# ATA5835 device description
Architecture: AVR8; Family: megaAVR
Registers are 8-bit, access not given, no defined reset value unless marked. A register's access mark holds for its fields unless they carry their own. Offsets are from the block's base; [hi:lo] are bit positions.

## RXDSP
Instances: RXDSP 0x00
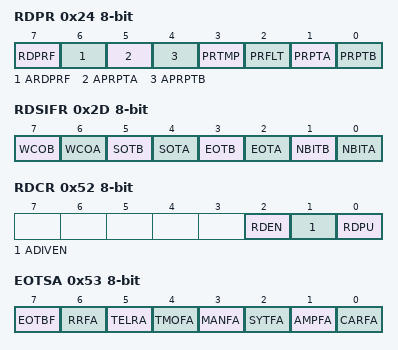
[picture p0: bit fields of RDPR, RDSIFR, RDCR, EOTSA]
0x24 RDPR — Rx DSP Power Reduction
  [7] RDPRF — Rx DSP Power Reduction Register Busy Flag
  [6] ARDPRF — Automatic Rx DSP Power Reduction Flag
  [5] APRPTA — Automatic Power Reduction Path A
  [4] APRPTB — Automatic Power Reduction Path B
  [3] PRTMP — Power Reduction Temperature Measurement
  [2] PRFLT — Power Reduction Digital Channel Filter
  [1] PRPTA — Power Reduction Demodulator and Receiving Path A
  [0] PRPTB — Power Reduction Demodulator and Receiving Path B
0x2D RDSIFR — Rx DSP Status Interrupt Flag Register
  [7] WCOB — Wake Check Ok Path B
  [6] WCOA — Wake Check Ok Path A
  [5] SOTB — Start Of Telegram Path B
  [4] SOTA — Start Of Telegram Path A
  [3] EOTB — End Of Telegram Path B
  [2] EOTA — End Of Telegram Path A
  [1] NBITB — New Bit Path B
  [0] NBITA — New Bit Path A
0x52 RDCR — Rx DSP Control Register
  [2] RDEN — Rx DSP Enable
  [1] ADIVEN — Divided ADC Clock Enable
  [0] RDPU — Rx DSP Power Up
0x53 EOTSA — End Of Telegram Status Path A
  [7] EOTBF — End Of Telegram Path B Fail
  [6] RRFA — RSSI Range Fail Path A
  [5] TELRA — Telegram Length Reached Path A
  [4] TMOFA — Time-Out Fail Path A
  [3] MANFA — Manchester Coding Fail Path A
  [2] SYTFA — Symbol Timing Fail Path A
  [1] AMPFA — Modulation Amplitude Fail Path A
  [0] CARFA — RF Carrier Fail Path A
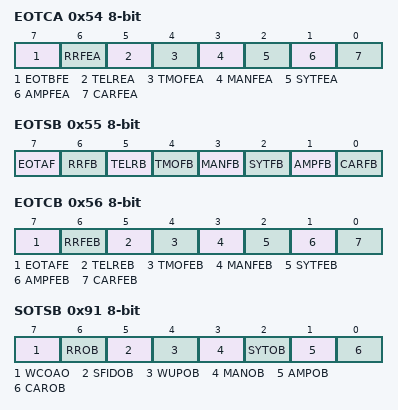
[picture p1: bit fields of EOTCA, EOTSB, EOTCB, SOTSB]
0x54 EOTCA — End Of Telegram Conditions Path A
  [7] EOTBFE — End Of Telegram Path B Fail Enable
  [6] RRFEA — RSSI Range Fail Enable Path A
  [5] TELREA — Telegram Length Reached Enable Path A
  [4] TMOFEA — Time-Out Fail Enable Path A
  [3] MANFEA — Manchester Coding Fail Enable Path A
  [2] SYTFEA — Symbol Timing Fail Enable Path A
  [1] AMPFEA — Modulation Amplitude Fail Enable Path A
  [0] CARFEA — RF Carrier Fail Enable Path A
0x55 EOTSB — End Of Telegram Status Path B
  [7] EOTAF — End Of Telegram Path A Fail
  [6] RRFB — RSSI Range Fail Path B
  [5] TELRB — Telegram Length Reached Path B
  [4] TMOFB — Time-Out Fail Path B
  [3] MANFB — Manchester Coding Fail Path B
  [2] SYTFB — Symbol Timing Fail Path B
  [1] AMPFB — Modulation Amplitude Fail Path B
  [0] CARFB — RF Carrier Fail Path B
0x56 EOTCB — End Of Telegram Conditions Path B
  [7] EOTAFE — End Of Telegram Path A Fail Enable
  [6] RRFEB — RSSI Range Fail Enable Path B
  [5] TELREB — Telegram Length Reached Enable Path B
  [4] TMOFEB — Time-Out Fail Enable Path B
  [3] MANFEB — Manchester Coding Fail Enable Path B
  [2] SYTFEB — Symbol Timing Fail Enable Path B
  [1] AMPFEB — Modulation Amplitude Fail Enable Path B
  [0] CARFEB — RF Carrier Fail Enable Path B
0x91 SOTSB — Start Of Telegram Status Path B
  [7] WCOAO — Wake Check Ok Path A Ok
  [6] RROB — RSSI Range Ok Path B
  [5] SFIDOB — Start of Frame Identifier Ok Path B
  [4] WUPOB — Wake Up Pattern Ok Path B
  [3] MANOB — Manchester Coding Ok Path B
  [2] SYTOB — Symbol Timing Ok Path B
  [1] AMPOB — Modulation Amplitude Ok Path B
  [0] CAROB — RF Carrier Ok Path B
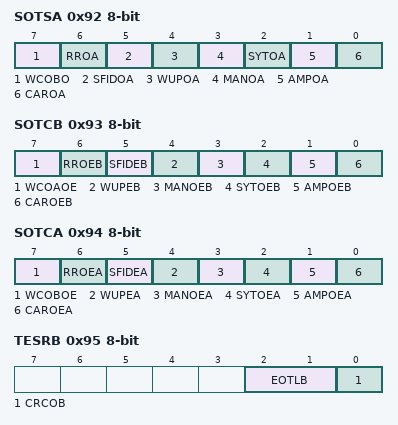
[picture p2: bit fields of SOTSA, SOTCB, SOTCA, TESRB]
0x92 SOTSA — Start Of Telegram Status Path A
  [7] WCOBO — Wake Check Ok Path B Ok
  [6] RROA — RSSI Range Ok Path A
  [5] SFIDOA — Start of Frame Identifier Ok Path A
  [4] WUPOA — Wake Up Pattern Ok Path A
  [3] MANOA — Manchester Coding Ok Path A
  [2] SYTOA — Symbol Timing Ok Path A
  [1] AMPOA — Modulation Amplitude Ok Path A
  [0] CAROA — RF Carrier Ok Path A
0x93 SOTCB — Start Of Telegram Conditions Path B
  [7] WCOAOE — Wake Check Ok Path A Ok Enable
  [6] RROEB — RSSI Range Ok Enable Path B
  [5] SFIDEB — Start of Frame Identifier Enable Path B
  [4] WUPEB — Wake Up Pattern Enable Path B
  [3] MANOEB — Manchester Coding Ok Enable Path B
  [2] SYTOEB — Symbol Timing Ok Enable Path B
  [1] AMPOEB — Modulation Amplitude Ok Enable Path B
  [0] CAROEB — RF Carrier Ok Enable Path B
0x94 SOTCA — Start Of Telegram Conditions Path A
  [7] WCOBOE — Wake Check Ok Path B Ok Enable
  [6] RROEA — RSSI Range Ok Enable Path A
  [5] SFIDEA — Start of Frame Identifier Enable Path A
  [4] WUPEA — Wake Up Pattern Enable Path A
  [3] MANOEA — Manchester Coding Ok Enable Path A
  [2] SYTOEA — Symbol Timing Ok Enable Path A
  [1] AMPOEA — Modulation Amplitude Ok Enable Path A
  [0] CAROEA — RF Carrier Ok Enable Path A
0x95 TESRB — Telegram Status Register Path B
  [2:1] EOTLB — End of Telegram Location Path B
    0=No EOT; 1=Before WCO; 2=Between WCO and SOT; 3=After SOT
  [0] CRCOB — Cyclic Redundancy Check Ok Path B
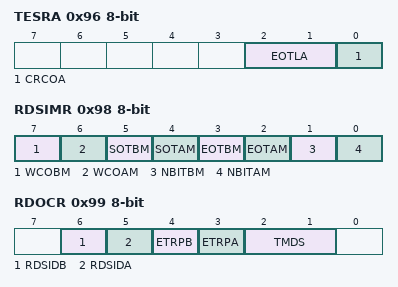
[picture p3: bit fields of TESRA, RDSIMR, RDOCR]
0x96 TESRA — Telegram Status Register Path A
  [2:1] EOTLA — End of Telegram Location Path A
    0=No EOT; 1=Before WCO; 2=Between WCO and SOT; 3=After SOT
  [0] CRCOA — Cyclic Redundancy Check Ok Path A
0x98 RDSIMR — Rx DSP Status Interrupt Mask Register
  [7] WCOBM — Wake Check Ok Path B Interrupt Mask
  [6] WCOAM — Wake Check Ok Path A Interrupt Mask
  [5] SOTBM — Start Of Telegram Path B Interrupt Mask
  [4] SOTAM — Start Of Telegram Path A Interrupt Mask
  [3] EOTBM — End Of Telegram Path B Interrupt Mask
  [2] EOTAM — End Of Telegram Path A Interrupt Mask
  [1] NBITBM — New Bit Path B Interrupt Mask
  [0] NBITAM — New Bit Path A Interrupt Mask
0x99 RDOCR — Rx DSP Output Control
  [6] RDSIDB — Rx DSP Start Bit Is Data Path B
  [5] RDSIDA — Rx DSP Start Bit Is Data Path A
  [4] ETRPB — Enable Transparent Raw Data Path B
  [3] ETRPA — Enable Transparent Raw Data Path A
  [2:1] TMDS — Transparent Mode Data Select
0x9B TEMP 16-bit — Temperature
